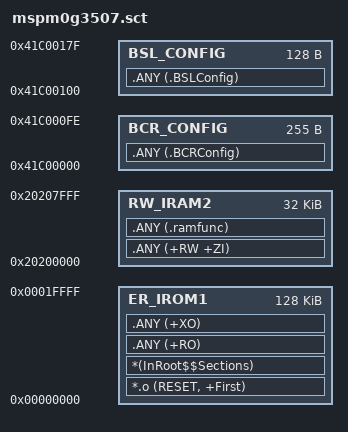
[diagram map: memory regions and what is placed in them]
/*****************************************************************************

  Copyright (C) 2024 Texas Instruments Incorporated - http://www.ti.com/ 

  Redistribution and use in source and binary forms, with or without 
  modification, are permitted provided that the following conditions 
  are met:

   Redistributions of source code must retain the above copyright 
   notice, this list of conditions and the following disclaimer.

   Redistributions in binary form must reproduce the above copyright
   notice, this list of conditions and the following disclaimer in the 
   documentation and/or other materials provided with the   
   distribution.

   Neither the name of Texas Instruments Incorporated nor the names of
   its contributors may be used to endorse or promote products derived
   from this software without specific prior written permission.

  THIS SOFTWARE IS PROVIDED BY THE COPYRIGHT HOLDERS AND CONTRIBUTORS 
  "AS IS" AND ANY EXPRESS OR IMPLIED WARRANTIES, INCLUDING, BUT NOT 
  LIMITED TO, THE IMPLIED WARRANTIES OF MERCHANTABILITY AND FITNESS FOR
  A PARTICULAR PURPOSE ARE DISCLAIMED. IN NO EVENT SHALL THE COPYRIGHT 
  OWNER OR CONTRIBUTORS BE LIABLE FOR ANY DIRECT, INDIRECT, INCIDENTAL, 
  SPECIAL, EXEMPLARY, OR CONSEQUENTIAL DAMAGES (INCLUDING, BUT NOT 
  LIMITED TO, PROCUREMENT OF SUBSTITUTE GOODS OR SERVICES; LOSS OF USE,
  DATA, OR PROFITS; OR BUSINESS INTERRUPTION) HOWEVER CAUSED AND ON ANY
  THEORY OF LIABILITY, WHETHER IN CONTRACT, STRICT LIABILITY, OR TORT 
  (INCLUDING NEGLIGENCE OR OTHERWISE) ARISING IN ANY WAY OUT OF THE USE 
  OF THIS SOFTWARE, EVEN IF ADVISED OF THE POSSIBILITY OF SUCH DAMAGE.

*****************************************************************************/

/*
================================================================================
MSPM0G3507 Keil 链接内存布局模块
================================================================================
【功能简介】
本文件定义应用 Flash、SRAM 以及 BCR/BSL 保留区的加载与执行区域，供 Keil
链接器放置代码、只读数据、可读写数据、零初始化数据和特殊配置段。

================================================================================
【函数定义】
本文件不定义函数。
- LR_IROM1/ER_IROM1/RW_IRAM1：应用程序 Flash 与 SRAM 区域。
- LR_BCR/LR_BSL：MSPM0 启动配置和引导加载器保留区域。

================================================================================
【使用说明】
1. 目标芯片 Flash/RAM 容量不变时不要修改本文件。
2. 新增固定地址数据前先核对 TI 数据手册及现有 BCR/BSL 保留区。
3. 修改后必须在 Keil 中重新链接并检查 map 文件是否存在区域溢出。
================================================================================
*/
; *************************************************************
; *** Scatter-Loading Description File generated by uVision ***
; *************************************************************

LR_IROM1 0x00000000 0x00020000  {    ; load region size_region
  ER_IROM1 0x00000000 ALIGNALL 8 0x00020000  {  ; load address = execution address
   *.o (RESET, +First)
   *(InRoot$$Sections)
   .ANY (+RO)
   .ANY (+XO)
  }
  RW_IRAM2 0x20200000 0x00008000  {  ; RW data
   .ANY (+RW +ZI)
   .ANY (.ramfunc)
  }
}

LR_BCR 0x41C00000 0x00000100  {    ; load region size_region
  BCR_CONFIG 0x41C00000 0x000000FF{
	.ANY (.BCRConfig)
  }
}

LR_BSL 0x41C00100 0x00000100  {    ; load region size_region
   BSL_CONFIG 0x41C00100 0x00000080{
	.ANY (.BSLConfig)
  }
}
